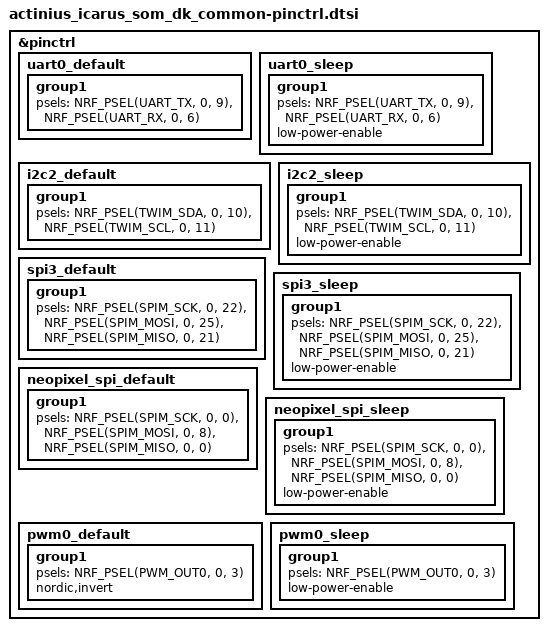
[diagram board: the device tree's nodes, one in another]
/*
 * Copyright (c) 2022 Actinius
 * SPDX-License-Identifier: Apache-2.0
 */

&pinctrl {
	uart0_default: uart0_default {
		group1 {
			psels = <NRF_PSEL(UART_TX, 0, 9)>,
				<NRF_PSEL(UART_RX, 0, 6)>;
		};
	};

	uart0_sleep: uart0_sleep {
		group1 {
			psels = <NRF_PSEL(UART_TX, 0, 9)>,
				<NRF_PSEL(UART_RX, 0, 6)>;
			low-power-enable;
		};
	};

	i2c2_default: i2c2_default {
		group1 {
			psels = <NRF_PSEL(TWIM_SDA, 0, 10)>,
				<NRF_PSEL(TWIM_SCL, 0, 11)>;
		};
	};

	i2c2_sleep: i2c2_sleep {
		group1 {
			psels = <NRF_PSEL(TWIM_SDA, 0, 10)>,
				<NRF_PSEL(TWIM_SCL, 0, 11)>;
			low-power-enable;
		};
	};

	spi3_default: spi3_default {
		group1 {
			psels = <NRF_PSEL(SPIM_SCK, 0, 22)>,
				<NRF_PSEL(SPIM_MOSI, 0, 25)>,
				<NRF_PSEL(SPIM_MISO, 0, 21)>;
		};
	};

	spi3_sleep: spi3_sleep {
		group1 {
			psels = <NRF_PSEL(SPIM_SCK, 0, 22)>,
				<NRF_PSEL(SPIM_MOSI, 0, 25)>,
				<NRF_PSEL(SPIM_MISO, 0, 21)>;
			low-power-enable;
		};
	};

	neopixel_spi_default: neopixel_spi_default {
		group1 {
			psels = <NRF_PSEL(SPIM_SCK, 0, 0)>,
				<NRF_PSEL(SPIM_MOSI, 0, 8)>,
				<NRF_PSEL(SPIM_MISO, 0, 0)>;
		};
	};

	neopixel_spi_sleep: neopixel_spi_sleep {
		group1 {
			psels = <NRF_PSEL(SPIM_SCK, 0, 0)>,
				<NRF_PSEL(SPIM_MOSI, 0, 8)>,
				<NRF_PSEL(SPIM_MISO, 0, 0)>;
			low-power-enable;
		};
	};

    pwm0_default: pwm0_default {
		group1 {
			psels = <NRF_PSEL(PWM_OUT0, 0, 3)>;
			nordic,invert;
		};
	};

	pwm0_sleep: pwm0_sleep {
		group1 {
			psels = <NRF_PSEL(PWM_OUT0, 0, 3)>;
			low-power-enable;
		};
	};

};
